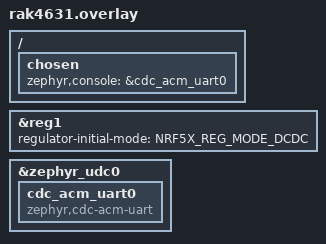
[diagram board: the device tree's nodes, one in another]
/ {
	chosen {
		zephyr,console = &cdc_acm_uart0;
	};
};

&reg1 {
	regulator-initial-mode = <NRF5X_REG_MODE_DCDC>;
};

&zephyr_udc0 {
	cdc_acm_uart0: cdc_acm_uart0 {
		compatible = "zephyr,cdc-acm-uart";
	};
};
